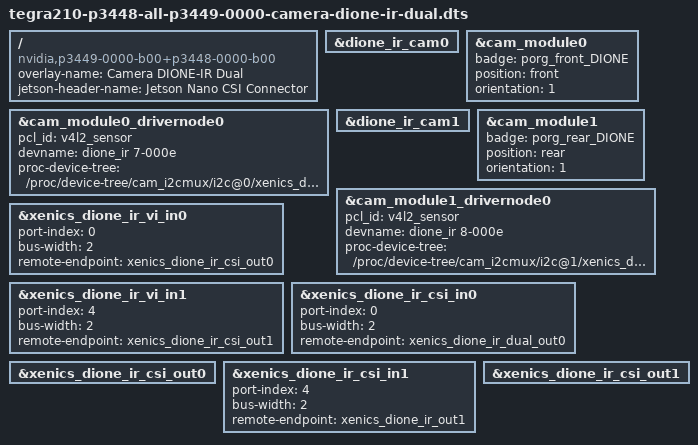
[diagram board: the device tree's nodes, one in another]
// SPDX-License-Identifier: GPL-2.0-only
/*
 * Jetson Device-tree overlay for Camera DIONE-IR for t210 dual
 * cam connector baseboards
 *
 * Copyright (c) 2021-2023, Xenics Infrared Solutions. All rights reserved.
 *
 */

/dts-v1/;
/plugin/;

/ {
	overlay-name = "Camera DIONE-IR Dual";
	jetson-header-name = "Jetson Nano CSI Connector";
	compatible = "nvidia,p3449-0000-b00+p3448-0000-b00", "nvidia,p3449-0000-b00+p3448-0002-b00";

	/* DIONE-IR dual sensor module */
	fragment@0 {
		target = <&dione_ir_cam0>;
		__overlay__ {
			status = "okay";
		};
	};
	fragment@1 {
		target = <&cam_module0>;
		__overlay__ {
			status = "okay";
			badge = "porg_front_DIONE";
			position = "front";
			orientation = "1";
		};
	};
	fragment@2 {
		target = <&cam_module0_drivernode0>;
		__overlay__ {
			status = "okay";
			pcl_id = "v4l2_sensor";
			devname = "dione_ir 7-000e";
			proc-device-tree = "/proc/device-tree/cam_i2cmux/i2c@0/xenics_dione_ir_a@0e";
		};
	};
	fragment@3 {
		target = <&dione_ir_cam1>;
		__overlay__ {
			status = "okay";
		};
	};
	fragment@4 {
		target = <&cam_module1>;
		__overlay__ {
			status = "okay";
			badge = "porg_rear_DIONE";
			position = "rear";
			orientation = "1";
		};
	};
	fragment@5 {
		target = <&cam_module1_drivernode0>;
		__overlay__ {
			status = "okay";
			pcl_id = "v4l2_sensor";
			devname = "dione_ir 8-000e";
			proc-device-tree = "/proc/device-tree/cam_i2cmux/i2c@1/xenics_dione_ir_e@0e";
		};
	};

	fragment@6 {
		target = <&xenics_dione_ir_vi_in0>;
		__overlay__ {
			status = "okay";
			port-index = <0>;
			bus-width = <2>;
			remote-endpoint = <&xenics_dione_ir_csi_out0>;
		};
	};
	fragment@7 {
		target = <&xenics_dione_ir_vi_in1>;
		__overlay__ {
			status = "okay";
			port-index = <4>;
			bus-width = <2>;
			remote-endpoint = <&xenics_dione_ir_csi_out1>;
		};
	};
	fragment@8 {
		target = <&xenics_dione_ir_csi_in0>;
		__overlay__ {
			status = "okay";
			port-index = <0>;
			bus-width = <2>;
			remote-endpoint = <&xenics_dione_ir_dual_out0>;
		};
	};
	fragment@9 {
		target = <&xenics_dione_ir_csi_out0>;
		__overlay__ {
			status = "okay";
		};
	};
	fragment@10 {
		target = <&xenics_dione_ir_csi_in1>;
		__overlay__ {
			status = "okay";
			port-index = <4>;
			bus-width = <2>;
			remote-endpoint = <&xenics_dione_ir_out1>;
		};
	};
	fragment@12 {
		target = <&xenics_dione_ir_csi_out1>;
		__overlay__ {
			status = "okay";
		};
	};
};
